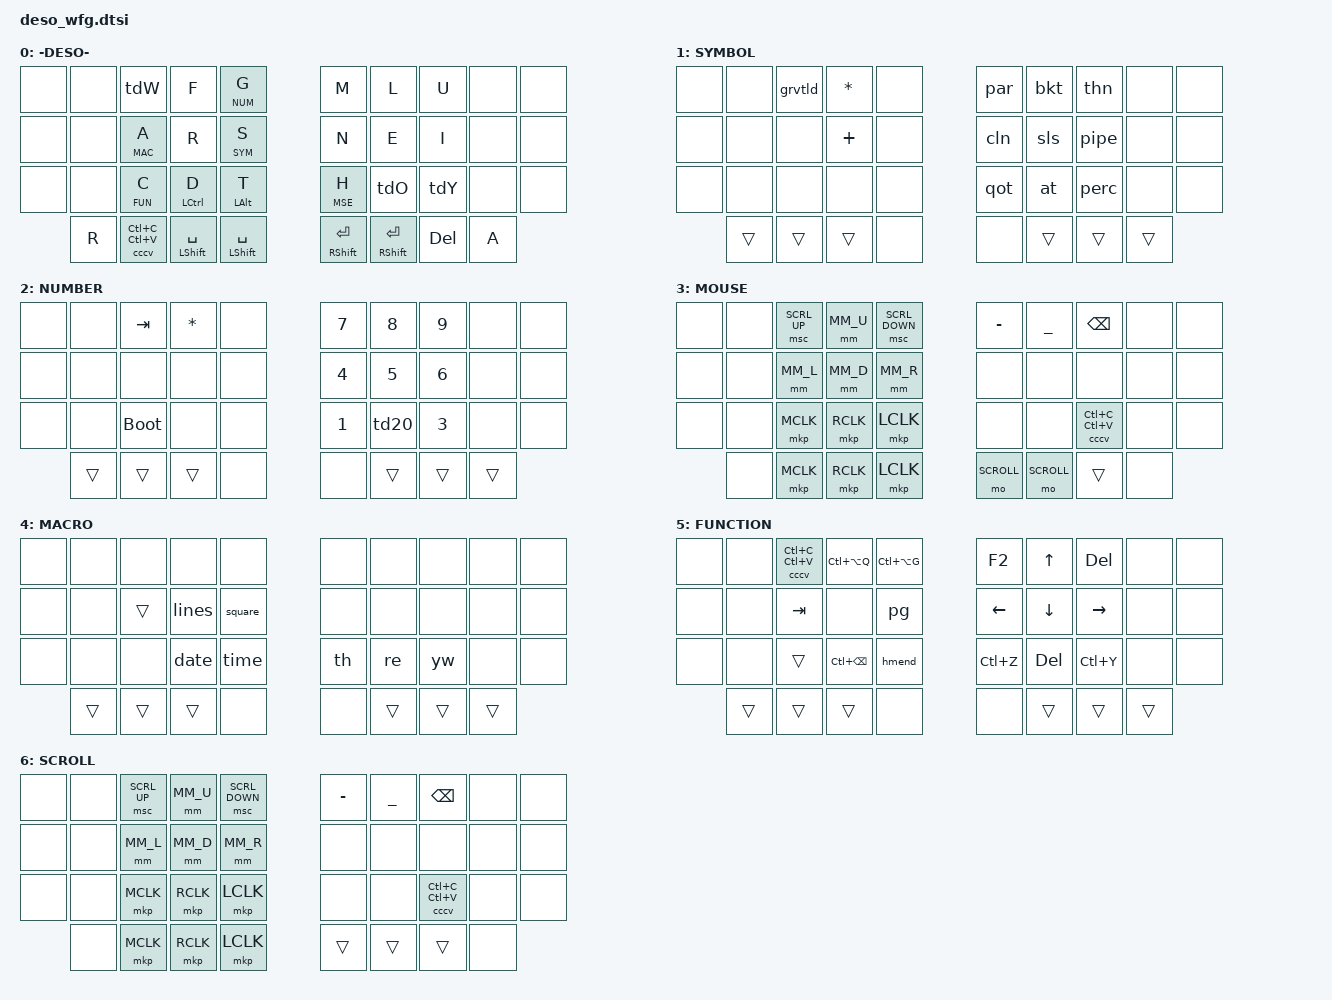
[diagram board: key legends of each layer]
/*
 * Last Update 10/5/24
 * WFG 19x2
 * 
 */

#include <behaviors.dtsi>
#include <dt-bindings/zmk/keys.h>
#include <dt-bindings/zmk/bt.h>
#include <dt-bindings/zmk/outputs.h>
#include <dt-bindings/zmk/mouse.h>
#include <input/processors.dtsi>
#include <dt-bindings/zmk/input_transform.h>
#include <zephyr/dt-bindings/input/input-event-codes.h>
#include "combos_3col.dtsi"
#include "macros.dtsi"
#include "behaviors.dtsi"

// Layer aliases
#define DEFAULT  0
#define SYMBOL   1
#define NUMBER   2
#define MOUSE    3
#define MACRO    4
#define FUNCTION 5
#define SCROLL   6

// Short defines
// #define D_LT   LC(LG(LEFT))
// #define D_RT   LC(LG(RIGHT))
// #define TAB_RT LC(TAB)
// #define TAB_LT LC(LS(TAB))
// #define LCC K_COPY
// #define LCV K_PASTE
#define SFTENT &mt RSHIFT RET
#define SFTSPC &mt LSHIFT SPC
#define CPST &cccv LC(C) LC(V)
#define CLIP &kp LC(LA(Q))
#define GSHT &kp LC(LA(G))

&mt {
    flavor = "hold-preferred";
    tapping-term-ms = <160>;
};

&lt {
    flavor = "balanced";
    tapping-term-ms = <150>;
};



#ifndef MOVE_Y
#define MOVE_Y(n) (0)
#endif
#ifndef MOVE_X
#define MOVE_X(n) (0)
#endif

#define U_MOUSE_MOVE_MAX 1700
#define MM_U MOVE_Y(-U_MOUSE_MOVE_MAX)
#define MM_D MOVE_Y(U_MOUSE_MOVE_MAX)
#define MM_L MOVE_X(-U_MOUSE_MOVE_MAX)
#define MM_R MOVE_X(U_MOUSE_MOVE_MAX)

/ {
    to_wheel: to_wheel {
        compatible = "zmk,input-processor-code-mapper";
        #input-processor-cells = <0>;
        type = <INPUT_EV_REL>;
        map = <INPUT_REL_X INPUT_REL_HWHEEL>
            , <INPUT_REL_Y INPUT_REL_WHEEL>;
    };

    trackball_listener {
        input-processors = <&zip_temp_layer MOUSE 1200>;

        scroll {
            layers = <SCROLL>;
            input-processors = <&zip_xy_scaler 1 18>, <&to_wheel>, <&zip_scroll_transform (INPUT_TRANSFORM_Y_INVERT)>;
        };
    };

    // mapping the fake keys to mouse device tack to the layers
    mmv_input_listener {
        compatible = "zmk,input-listener";
        device = <&mm>;
        input-processors = <&zip_xy_scaler 1 1>, <&zip_temp_layer MOUSE 1200>;

        scroll {
            inherit;
            layers = <MOUSE>;
            input-processors = <&zip_xy_scaler 1 7>, <&to_wheel>, <&zip_scroll_transform (INPUT_TRANSFORM_Y_INVERT)>;
        };
    };

{
   keymap {
        compatible = "zmk,keymap";


// ---------------------------------------------------------------------------------------------------------------
// |   TAB   |    W   [Q]   F   [B]   G num|         |    X    |         |    M   [J]   L    |    U    |  BSPC   |
// |  SHIFT  | A macro[V]   R   [P]   S sym|         |    X    |         |    N   [K]   E   [!]   I    |  DEL    |
// |  XXXX   |  C  fn [Z]   D   [X]   T    |         |    X    |         | H mouse |  O tt,  |  Y  tt. |  XXXX   |
//                     |   CCCV  |SPC/SHFT | RETURN  |    X    |   SPC   | SPC/ENT |   Paste |
// ---------------------------------------------------------------------------------------------------------------
        default_layer {
            display-name = "-DESO-";            
            bindings = <
                &none &none &tdW &kp F &lt NUM G &kp M &kp L &kp U &none &none
                &none &none &lt MAC A &kp R &lt SYM S &kp N &kp E &kp I &none &none
                &none &none &lt FUN C &hrm LCTRL D &hrm LALT T &lt MSE H &tdO &tdY &none &none
                &kp R CPST  SFTSPC SFTSPC SFTENT SFTENT  &kp DEL &kp A
            >;
        };


        symbol_layer {
            display-name = "SYMBOL";
            bindings = <
                &none &none &grvtld &kp STAR &none &par &bkt &thn &none &none
                &none &none &none &kp PLUS &none &cln &sls &pipe &none &none
                &none &none &none &none &none &qot &at &perc &none &none
                &trans &trans &trans &none &none &trans &trans  &trans
            >;
        };

        number_layer {
            display-name = "NUMBER";
            bindings = <
                &none &none &kp TAB &kp STAR &none &kp N7 &kp N8 &kp N9 &none &none
                &none &none &none &none &none &kp N4 &kp N5 &kp N6 &none &none
                &none &none &bootloader &none &none &kp N1 &td20 &kp N3 &none &none
                       &trans &trans &trans &none &none &trans &trans &trans
            >;
        };

        mouse_layer {
            display-name = "MOUSE";
            bindings = <
                &none &none &msc SCRL_UP &mm MM_U &msc SCRL_DOWN &kp MINUS &kp UNDER &kp BSPC &none &none
                &none &none &mm MM_L &mm MM_D &mm MM_R &none &none &none &none &none
                &none &none &mkp MCLK &mkp RCLK &mkp LCLK &none &none CPST &none &none
                      &none &mkp MCLK &mkp RCLK &mkp LCLK &mo SCROLL &mo SCROLL &trans &none
            >;
        };

        macro_layer {
            display-name = "MACRO";
            bindings = <
                &none &none &none &none &none &none &none &none &none &none
                &none &none &trans &lines &square &none &none &none &none &none
                &none &none &none &date &time &th &re &yw &none &none
                      &trans &trans &trans &none &none &trans &trans &trans
            >;
        };

        function_layer {
            display-name = "FUNCTION";    
            bindings = <
                &none &none CPST CLIP GSHT &kp F2 &kp UP &kp DEL &none &none
                &none &none &kp TAB &none &pg &kp LEFT &kp DOWN &kp RIGHT &none &none
                &none &none &trans &kp LC(BSPC) &hmend &kp LC(Z) &kp DEL &kp LC(Y) &none &none
                      &trans &trans &trans &none &none &trans &trans &trans
            >;
        };

        scroll_layer {
            display-name = "SCROLL";
            bindings = <
                &none &none &msc SCRL_UP &mm MM_U &msc SCRL_DOWN &kp MINUS &kp UNDER &kp BSPC &none &none
                &none &none &mm MM_L &mm MM_D &mm MM_R &none &none &none &none &none
                &none &none &mkp MCLK &mkp RCLK &mkp LCLK &none &none CPST &none &none
                      &none &mkp MCLK &mkp RCLK &mkp LCLK &trans &trans &trans &none
            >;
        };
    };
};
